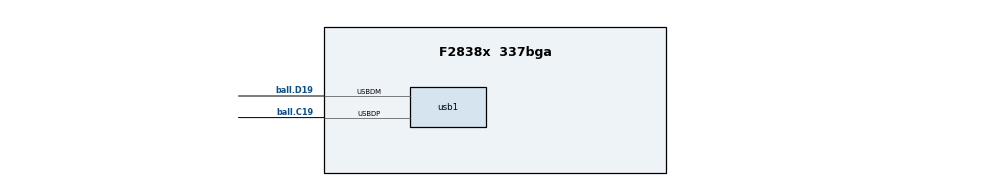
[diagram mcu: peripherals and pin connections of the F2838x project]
/**
 * @cliArgs --device "F2838x" --package "337bga" --part "F2838x_337bga" --product "C2000WARE@4.02.00.00"
 * @versions {"tool":"1.13.0+2411"}
 */

/**
 * Import the modules used in this configuration.
 */
const usb  = scripting.addModule("/driverlib/usb.js", {}, false);
const usb1 = usb.addInstance();

/**
 * Write custom configuration values to the imported modules.
 */
usb1.$name                  = "myUSB0";
usb1.registerInterrupts     = true;
usb1.usb.usbdmPin.$assign   = "ball.D19";
usb1.usb.usbdpPin.$assign   = "ball.C19";

usb1.usbLib.deviceClasses   = "Mouse";
usb1.dmQual.$name           = "myGPIOQUAL0";
usb1.dpQual.$name           = "myGPIOQUAL1";
usb1.USBInt.enableInterrupt = true;

/**
 * Pinmux solution for unlocked pins/peripherals. This ensures that minor changes to the automatic solver in a future
 * version of the tool will not impact the pinmux you originally saw.  These lines can be completely deleted in order to
 * re-solve from scratch.
 */
usb1.usb.$suggestSolution = "USB0";
